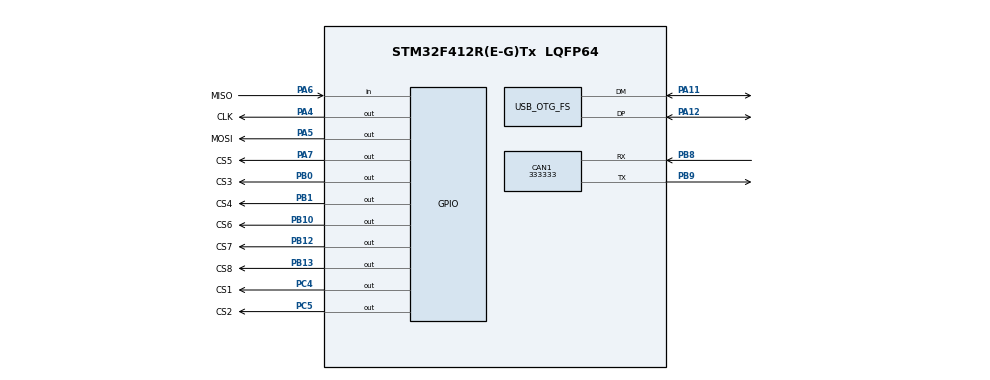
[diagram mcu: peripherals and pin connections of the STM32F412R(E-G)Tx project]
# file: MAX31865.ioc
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CAN1.CalculateBaudRate=333333
CAN1.CalculateTimeBit=3000
CAN1.CalculateTimeQuantum=1000.0
Mcu.Family=STM32F4
Mcu.Name=STM32F412R(E-G)Tx
Mcu.Package=LQFP64
NVIC.PriorityGroup=NVIC_PRIORITYGROUP_4
PA11.Mode=Device_Only
PA11.Signal=USB_OTG_FS_DM
PA12.Mode=Device_Only
PA12.Signal=USB_OTG_FS_DP
PA13.Mode=Trace_Asynchronous_SW
PA13.Signal=SYS_JTMS-SWDIO
PA14.Mode=Trace_Asynchronous_SW
PA14.Signal=SYS_JTCK-SWCLK
PA4.GPIO_Label=CLK
PA4.Signal=GPIO_Output
PA5.GPIO_Label=MOSI
PA5.Signal=GPIO_Output
PA6.GPIO_Label=MISO
PA6.Signal=GPIO_Input
PA7.GPIO_Label=CS5
PA7.Signal=GPIO_Output
PB0.GPIO_Label=CS3
PB0.Signal=GPIO_Output
PB1.GPIO_Label=CS4
PB1.Signal=GPIO_Output
PB10.GPIO_Label=CS6
PB10.Signal=GPIO_Output
PB12.GPIO_Label=CS7
PB12.Signal=GPIO_Output
PB13.GPIO_Label=CS8
PB13.Signal=GPIO_Output
PB3.Mode=Trace_Asynchronous_SW
PB3.Signal=SYS_JTDO-SWO
PB8.Mode=CAN_Activate
PB8.Signal=CAN1_RX
PB9.Mode=CAN_Activate
PB9.Signal=CAN1_TX
PC4.GPIO_Label=CS1
PC4.Signal=GPIO_Output
PC5.GPIO_Label=CS2
PC5.Signal=GPIO_Output
PH0\ -\ OSC_IN.Mode=HSE-External-Oscillator
PH0\ -\ OSC_IN.Signal=RCC_OSC_IN
PH1\ -\ OSC_OUT.Mode=HSE-External-Oscillator
PH1\ -\ OSC_OUT.Signal=RCC_OSC_OUT
ProjectManager.HeapSize=0x200
ProjectManager.StackSize=0x400
ProjectManager.TargetToolchain=STM32CubeIDE
RCC.CortexFreq_Value=16000000
RCC.PLLM=15
RCC.PLLN=144
RCC.PLLQ=5
RCC.USBFreq_Value=48000000
RCC.VCOOutputFreq_Value=240000000
USB_OTG_FS.VirtualMode=Device_Only
board=custom

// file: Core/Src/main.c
/* USER CODE BEGIN Header */
/**
  ******************************************************************************
  * @file           : main.c
  * @brief          : Main program body
  ******************************************************************************
  * @attention
  *
  * Copyright (c) 2022 STMicroelectronics.
  * All rights reserved.
  *
  * This software is licensed under terms that can be found in the LICENSE file
  * in the root directory of this software component.
  * If no LICENSE file comes with this software, it is provided AS-IS.
  *
  ******************************************************************************
  */
/* USER CODE END Header */
#include "main.h"

/* USER CODE BEGIN Includes */
#include "MAX31865.h"
/* USER CODE END Includes */

CAN_HandleTypeDef hcan1;

PCD_HandleTypeDef hpcd_USB_OTG_FS;

void SystemClock_Config(void);
static void MX_GPIO_Init(void);
static void MX_CAN1_Init(void);
static void MX_USB_OTG_FS_PCD_Init(void);

int main(void)
{

  /* MCU Configuration--------------------------------------------------------*/

  /* Reset of all peripherals, Initializes the Flash interface and the Systick. */
  HAL_Init();

  /* Configure the system clock */
  SystemClock_Config();

  /* Initialize all configured peripherals */
  MX_GPIO_Init();
  MX_CAN1_Init();
  MX_USB_OTG_FS_PCD_Init();

  /* Infinite loop */
  while (1)
  {

  }
}

void SystemClock_Config(void)
{
  RCC_OscInitTypeDef RCC_OscInitStruct = {0};
  RCC_ClkInitTypeDef RCC_ClkInitStruct = {0};

  /** Configure the main internal regulator output voltage
  */
  __HAL_RCC_PWR_CLK_ENABLE();
  __HAL_PWR_VOLTAGESCALING_CONFIG(PWR_REGULATOR_VOLTAGE_SCALE1);

  /** Initializes the RCC Oscillators according to the specified parameters
  * in the RCC_OscInitTypeDef structure.
  */
  RCC_OscInitStruct.OscillatorType = RCC_OSCILLATORTYPE_HSI|RCC_OSCILLATORTYPE_HSE;
  RCC_OscInitStruct.HSEState = RCC_HSE_ON;
  RCC_OscInitStruct.HSIState = RCC_HSI_ON;
  RCC_OscInitStruct.HSICalibrationValue = RCC_HSICALIBRATION_DEFAULT;
  RCC_OscInitStruct.PLL.PLLState = RCC_PLL_ON;
  RCC_OscInitStruct.PLL.PLLSource = RCC_PLLSOURCE_HSE;
  RCC_OscInitStruct.PLL.PLLM = 15;
  RCC_OscInitStruct.PLL.PLLN = 144;
  RCC_OscInitStruct.PLL.PLLP = RCC_PLLP_DIV2;
  RCC_OscInitStruct.PLL.PLLQ = 5;
  RCC_OscInitStruct.PLL.PLLR = 2;
  if (HAL_RCC_OscConfig(&RCC_OscInitStruct) != HAL_OK)
  {
    Error_Handler();
  }

  /** Initializes the CPU, AHB and APB buses clocks
  */
  RCC_ClkInitStruct.ClockType = RCC_CLOCKTYPE_HCLK|RCC_CLOCKTYPE_SYSCLK
                              |RCC_CLOCKTYPE_PCLK1|RCC_CLOCKTYPE_PCLK2;
  RCC_ClkInitStruct.SYSCLKSource = RCC_SYSCLKSOURCE_HSI;
  RCC_ClkInitStruct.AHBCLKDivider = RCC_SYSCLK_DIV1;
  RCC_ClkInitStruct.APB1CLKDivider = RCC_HCLK_DIV1;
  RCC_ClkInitStruct.APB2CLKDivider = RCC_HCLK_DIV1;

  if (HAL_RCC_ClockConfig(&RCC_ClkInitStruct, FLASH_LATENCY_0) != HAL_OK)
  {
    Error_Handler();
  }
}

static void MX_CAN1_Init(void)
{

  hcan1.Instance = CAN1;
  hcan1.Init.Prescaler = 16;
  hcan1.Init.Mode = CAN_MODE_NORMAL;
  hcan1.Init.SyncJumpWidth = CAN_SJW_1TQ;
  hcan1.Init.TimeSeg1 = CAN_BS1_1TQ;
  hcan1.Init.TimeSeg2 = CAN_BS2_1TQ;
  hcan1.Init.TimeTriggeredMode = DISABLE;
  hcan1.Init.AutoBusOff = DISABLE;
  hcan1.Init.AutoWakeUp = DISABLE;
  hcan1.Init.AutoRetransmission = DISABLE;
  hcan1.Init.ReceiveFifoLocked = DISABLE;
  hcan1.Init.TransmitFifoPriority = DISABLE;
  if (HAL_CAN_Init(&hcan1) != HAL_OK)
  {
    Error_Handler();
  }

}

static void MX_USB_OTG_FS_PCD_Init(void)
{

  hpcd_USB_OTG_FS.Instance = USB_OTG_FS;
  hpcd_USB_OTG_FS.Init.dev_endpoints = 6;
  hpcd_USB_OTG_FS.Init.speed = PCD_SPEED_FULL;
  hpcd_USB_OTG_FS.Init.dma_enable = DISABLE;
  hpcd_USB_OTG_FS.Init.phy_itface = PCD_PHY_EMBEDDED;
  hpcd_USB_OTG_FS.Init.Sof_enable = DISABLE;
  hpcd_USB_OTG_FS.Init.low_power_enable = DISABLE;
  hpcd_USB_OTG_FS.Init.lpm_enable = DISABLE;
  hpcd_USB_OTG_FS.Init.battery_charging_enable = DISABLE;
  hpcd_USB_OTG_FS.Init.vbus_sensing_enable = DISABLE;
  hpcd_USB_OTG_FS.Init.use_dedicated_ep1 = DISABLE;
  if (HAL_PCD_Init(&hpcd_USB_OTG_FS) != HAL_OK)
  {
    Error_Handler();
  }

}

static void MX_GPIO_Init(void)
{
  GPIO_InitTypeDef GPIO_InitStruct = {0};

  /* GPIO Ports Clock Enable */
  __HAL_RCC_GPIOH_CLK_ENABLE();
  __HAL_RCC_GPIOA_CLK_ENABLE();
  __HAL_RCC_GPIOC_CLK_ENABLE();
  __HAL_RCC_GPIOB_CLK_ENABLE();

  /*Configure GPIO pin Output Level */
  HAL_GPIO_WritePin(GPIOA, CLK_Pin|MOSI_Pin|CS5_Pin, GPIO_PIN_RESET);

  /*Configure GPIO pin Output Level */
  HAL_GPIO_WritePin(GPIOC, CS1_Pin|CS2_Pin, GPIO_PIN_RESET);

  /*Configure GPIO pin Output Level */
  HAL_GPIO_WritePin(GPIOB, CS3_Pin|CS4_Pin|CS6_Pin|CS7_Pin
                          |CS8_Pin, GPIO_PIN_RESET);

  /*Configure GPIO pins : CLK_Pin MOSI_Pin CS5_Pin */
  GPIO_InitStruct.Pin = CLK_Pin|MOSI_Pin|CS5_Pin;
  GPIO_InitStruct.Mode = GPIO_MODE_OUTPUT_PP;
  GPIO_InitStruct.Pull = GPIO_NOPULL;
  GPIO_InitStruct.Speed = GPIO_SPEED_FREQ_LOW;
  HAL_GPIO_Init(GPIOA, &GPIO_InitStruct);

  /*Configure GPIO pin : MISO_Pin */
  GPIO_InitStruct.Pin = MISO_Pin;
  GPIO_InitStruct.Mode = GPIO_MODE_INPUT;
  GPIO_InitStruct.Pull = GPIO_NOPULL;
  HAL_GPIO_Init(MISO_GPIO_Port, &GPIO_InitStruct);

  /*Configure GPIO pins : CS1_Pin CS2_Pin */
  GPIO_InitStruct.Pin = CS1_Pin|CS2_Pin;
  GPIO_InitStruct.Mode = GPIO_MODE_OUTPUT_PP;
  GPIO_InitStruct.Pull = GPIO_NOPULL;
  GPIO_InitStruct.Speed = GPIO_SPEED_FREQ_LOW;
  HAL_GPIO_Init(GPIOC, &GPIO_InitStruct);

  /*Configure GPIO pins : CS3_Pin CS4_Pin CS6_Pin CS7_Pin
                           CS8_Pin */
  GPIO_InitStruct.Pin = CS3_Pin|CS4_Pin|CS6_Pin|CS7_Pin
                          |CS8_Pin;
  GPIO_InitStruct.Mode = GPIO_MODE_OUTPUT_PP;
  GPIO_InitStruct.Pull = GPIO_NOPULL;
  GPIO_InitStruct.Speed = GPIO_SPEED_FREQ_LOW;
  HAL_GPIO_Init(GPIOB, &GPIO_InitStruct);

}

void Error_Handler(void)
{
  __disable_irq();
  while (1)
  {
  }
}
